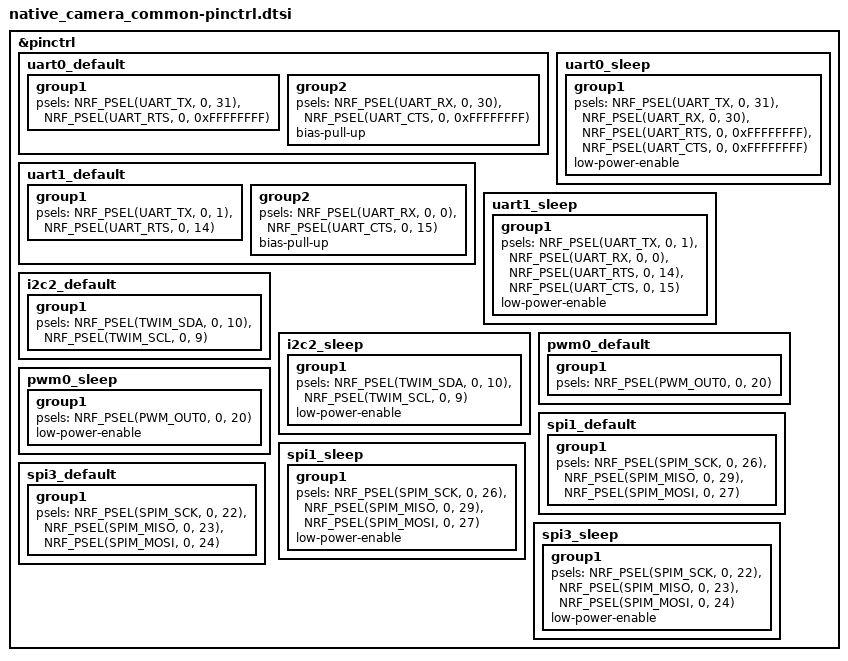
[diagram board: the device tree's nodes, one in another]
/*
 * Copyright (c) 2022 Nordic Semiconductor
 * SPDX-License-Identifier: Apache-2.0
 */

&pinctrl {
	uart0_default: uart0_default {
		group1 {
			psels = <NRF_PSEL(UART_TX, 0, 31)>,
				<NRF_PSEL(UART_RTS, 0, 0xFFFFFFFF)>;
		};
		group2 {
			psels = <NRF_PSEL(UART_RX, 0, 30)>,
				<NRF_PSEL(UART_CTS, 0, 0xFFFFFFFF)>;
			bias-pull-up;
		};
	};

	uart0_sleep: uart0_sleep {
		group1 {
			psels = <NRF_PSEL(UART_TX, 0, 31)>,
				<NRF_PSEL(UART_RX, 0, 30)>,
				<NRF_PSEL(UART_RTS, 0, 0xFFFFFFFF)>,
				<NRF_PSEL(UART_CTS, 0, 0xFFFFFFFF)>;
			low-power-enable;
		};
	};

	uart1_default: uart1_default {
		group1 {
			psels = <NRF_PSEL(UART_TX, 0, 1)>,
				<NRF_PSEL(UART_RTS, 0, 14)>;
		};
		group2 {
			psels = <NRF_PSEL(UART_RX, 0, 0)>,
				<NRF_PSEL(UART_CTS, 0, 15)>;
			bias-pull-up;
		};
	};

	uart1_sleep: uart1_sleep {
		group1 {
			psels = <NRF_PSEL(UART_TX, 0, 1)>,
				<NRF_PSEL(UART_RX, 0, 0)>,
				<NRF_PSEL(UART_RTS, 0, 14)>,
				<NRF_PSEL(UART_CTS, 0, 15)>;
			low-power-enable;
		};
	};

	i2c2_default: i2c2_default {
		group1 {
			psels = <NRF_PSEL(TWIM_SDA, 0, 10)>,
				<NRF_PSEL(TWIM_SCL, 0, 9)>;
		};
	};

	i2c2_sleep: i2c2_sleep {
		group1 {
			psels = <NRF_PSEL(TWIM_SDA, 0, 10)>,
				<NRF_PSEL(TWIM_SCL, 0, 9)>;
			low-power-enable;
		};
	};

	pwm0_default: pwm0_default {
		group1 {
			psels = <NRF_PSEL(PWM_OUT0, 0, 20)>;
		};
	};

	pwm0_sleep: pwm0_sleep {
		group1 {
			psels = <NRF_PSEL(PWM_OUT0, 0, 20)>;
			low-power-enable;
		};
	};

	spi1_default: spi1_default {
		group1 {
			psels = <NRF_PSEL(SPIM_SCK, 0, 26)>,
				<NRF_PSEL(SPIM_MISO, 0, 29)>,
				<NRF_PSEL(SPIM_MOSI, 0, 27)>;
		};
	};

	spi1_sleep: spi1_sleep {
		group1 {
			psels = <NRF_PSEL(SPIM_SCK, 0, 26)>,
				<NRF_PSEL(SPIM_MISO, 0, 29)>,
				<NRF_PSEL(SPIM_MOSI, 0, 27)>;
			low-power-enable;
		};
	};

	spi3_default: spi3_default {
		group1 {
			psels = <NRF_PSEL(SPIM_SCK, 0, 22)>,
				<NRF_PSEL(SPIM_MISO, 0, 23)>,
				<NRF_PSEL(SPIM_MOSI, 0, 24)>;
		};
	};

	spi3_sleep: spi3_sleep {
		group1 {
			psels = <NRF_PSEL(SPIM_SCK, 0, 22)>,
				<NRF_PSEL(SPIM_MISO, 0, 23)>,
				<NRF_PSEL(SPIM_MOSI, 0, 24)>;
			low-power-enable;
		};
	};
};
